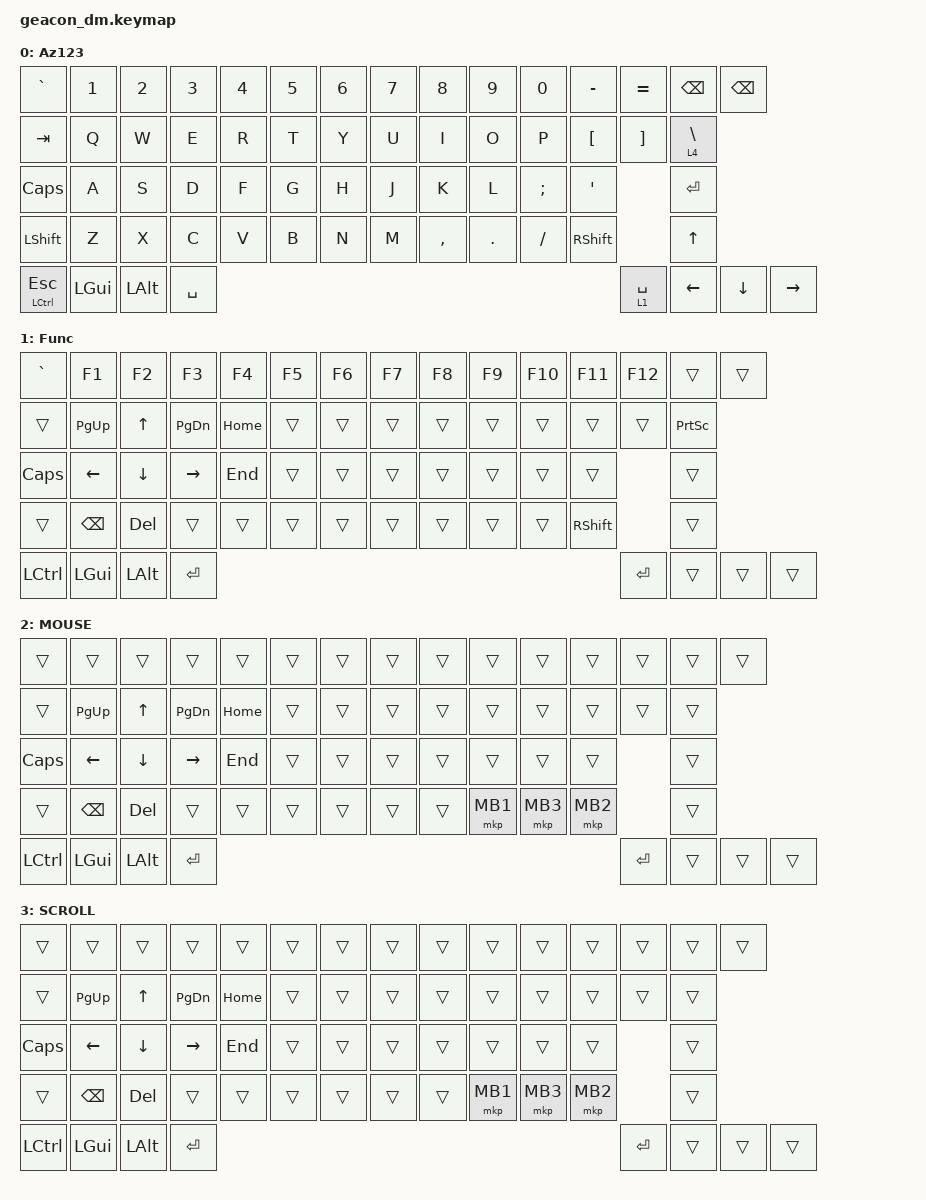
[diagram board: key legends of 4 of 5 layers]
#include <behaviors.dtsi>
#include <dt-bindings/zmk/keys.h>
#include <dt-bindings/zmk/pointing.h>
#include <dt-bindings/zmk/bt.h>
#include <behaviors/rgbled_widget.dtsi>

#define MOUSE 2
#define SCROLL 3
#define BT 4

&mt {
   flavor = "tap-preferred";
   quick_tap_ms = <125>;
   tapping_term_ms = <250>;
};
 
/ {
    macros {
        to_layer_0: to_layer_0 {
            compatible = "zmk,behavior-macro-one-param";
            #binding-cells = <1>;
            bindings = <&to 0 &macro_param_1to1 &kp MACRO_PLACEHOLDER>;
            label = "TO_LAYER_0";
        };
    };

    behaviors {
        lt_to_layer_0: lt_to_layer_0 {
            compatible = "zmk,behavior-hold-tap";
            label = "LAYER_TAP_TO_0";
            bindings = <&mo>, <&to_layer_0>;

            #binding-cells = <2>;
            tapping-term-ms = <200>;
        };
    }; 
 
   keymap {
       compatible = "zmk,keymap";
       default_layer {
           label = "Az123";
           bindings = <
&kp GRAVE &kp N1    &kp N2     &kp N3     &kp N4     &kp N5       &kp N6    &kp N7     &kp N8     &kp N9     &kp N0    &kp MINUS   &kp EQUAL   &kp BKSP &kp BKSP
&kp TAB   &kp Q     &kp W      &kp E      &kp R      &kp T        &kp Y     &kp U      &kp I      &kp O      &kp P     &kp LBKT    &kp RBKT        &lt 4 BSLH
&kp CAPS  &kp A     &kp S      &kp D      &kp F      &kp G        &kp H     &kp J      &kp K      &kp L      &kp SEMI  &kp SQT                     &kp ENTER
&kp LSHFT &kp Z     &kp X      &kp C      &kp V      &kp B        &kp N     &kp M      &kp COMMA  &kp DOT    &kp FSLH  &kp RSHFT                   &kp UP
&mt LCTL ESC  &kp LGUI   &kp LALT      &kp SPACE     &lt 1 SPACE                                                                          &kp LEFT &kp DOWN &kp RIGHT
>;
       };
 
       function_layer {
           label = "Func";
           bindings = <
&kp GRAVE &kp F1    &kp F2     &kp F3     &kp F4     &kp F5       &kp F6    &kp F7     &kp F8     &kp F9     &kp F10   &kp F11     &kp F12     &trans &trans
&trans    &kp PG_UP &kp UP     &kp PG_DN  &kp HOME   &trans       &trans    &trans     &trans     &trans     &trans    &trans      &trans          &kp PSCRN
&kp CAPS  &kp LEFT  &kp DOWN   &kp RIGHT  &kp END    &trans       &trans    &trans     &trans     &trans     &trans    &trans                      &trans
&trans    &kp BKSP  &kp DEL    &trans     &trans     &trans       &trans    &trans     &trans     &trans     &trans    &kp RSHFT                   &trans
&kp LCTL   &kp LGUI   &kp LALT         &kp ENTER     &kp ENTER                                                                            &trans   &trans   &trans
>;
       };

       mouse_layer {
           display-name = "MOUSE";    
           label = "MOUSE";
           bindings = <
&trans    &trans    &trans     &trans     &trans     &trans       &trans    &trans     &trans     &trans     &trans    &trans      &trans      &trans &trans
&trans    &kp PG_UP &kp UP     &kp PG_DN  &kp HOME   &trans       &trans    &trans     &trans     &trans     &trans    &trans      &trans          &trans
&kp CAPS  &kp LEFT  &kp DOWN   &kp RIGHT  &kp END    &trans       &trans    &trans     &trans     &trans     &trans    &trans                      &trans
&trans    &kp BKSP  &kp DEL    &trans     &trans     &trans       &trans    &trans     &trans     &mkp MB1   &mkp MB3  &mkp MB2                    &trans
&kp LCTL   &kp LGUI   &kp LALT         &kp ENTER     &kp ENTER                                                                          &trans   &trans   &trans
>;
       };

       scroll_layer {
           display-name = "SCROLL";    
           label = "SCROLL";
           bindings = <
&trans    &trans    &trans     &trans     &trans     &trans       &trans    &trans     &trans     &trans     &trans    &trans      &trans      &trans &trans
&trans    &kp PG_UP &kp UP     &kp PG_DN  &kp HOME   &trans       &trans    &trans     &trans     &trans     &trans    &trans      &trans          &trans
&kp CAPS  &kp LEFT  &kp DOWN   &kp RIGHT  &kp END    &trans       &trans    &trans     &trans     &trans     &trans    &trans                      &trans
&trans    &kp BKSP  &kp DEL    &trans     &trans     &trans       &trans    &trans     &trans     &mkp MB1   &mkp MB3  &mkp MB2                    &trans
&kp LCTL   &kp LGUI   &kp LALT         &kp ENTER     &kp ENTER                                                                          &trans   &trans   &trans
>;
       };

        bt_layer {
           display-name = "BT";    
           label = "BT";
           bindings = <
&bt BT_CLR     &bt BT_SEL 0 &bt BT_SEL 1 &bt BT_SEL 2 &bt BT_SEL 3 &bt BT_SEL 4  &trans  &trans  &trans  &trans  &trans  &trans  &trans  &trans   &trans &trans
&bt BT_CLR_ALL &trans       &trans       &trans       &trans       &trans        &trans  &trans  &trans  &trans  &trans  &trans  &trans              &trans
&trans         &trans       &trans       &trans       &trans       &trans        &trans  &trans  &trans  &trans  &trans  &trans                      &trans
&trans         &trans       &trans       &trans       &trans       &trans        &trans  &trans  &trans  &trans  &trans  &trans                      &trans
&trans         &trans       &trans       &trans       &trans                                                                                &trans   &trans   &trans
>;
    };
  };
};

/ {
    aliases {
        led-red = &led0;
        led-green = &led1;
        led-blue = &led2;
    };

    leds {
        compatible = "gpio-leds";
        status = "okay";
        led0: led_0 {
            gpios = <&gpio0 26 GPIO_ACTIVE_LOW>;  // red LED, connected to P0.26
        };
        led1: led_1 {
            gpios = <&gpio0 30 GPIO_ACTIVE_LOW>;  // green LED, connected to P0.30
        };
        led2: led_2 {
            gpios = <&gpio0 6 GPIO_ACTIVE_LOW>;  // blue LED, connected to P0.06
        };
    };
};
